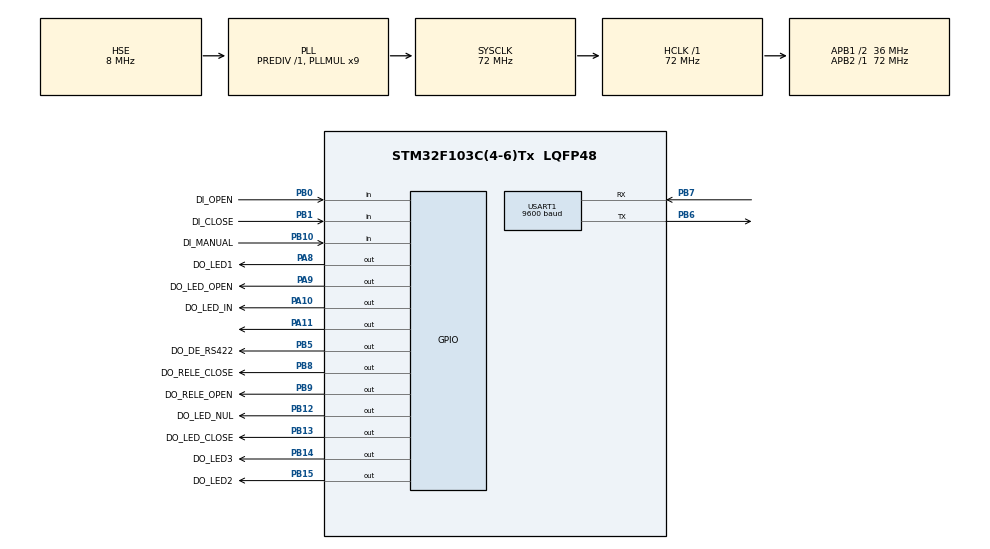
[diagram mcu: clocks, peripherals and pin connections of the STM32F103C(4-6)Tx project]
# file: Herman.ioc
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ADC1.Channel-0\#ChannelRegularConversion=ADC_CHANNEL_VREFINT
ADC1.NbrOfConversionFlag=1
ADC1.Rank-0\#ChannelRegularConversion=1
ADC1.SamplingTime-0\#ChannelRegularConversion=ADC_SAMPLETIME_1CYCLE_5
ADC1.master=1
FREERTOS.Tasks01=Task200mks,0,128,StartTask200mks,Default,NULL,Dynamic,NULL,NULL
FREERTOS.configTOTAL_HEAP_SIZE=1024
FREERTOS.configUSE_COUNTING_SEMAPHORES=1
IWDG.Prescaler=IWDG_PRESCALER_256
Mcu.Family=STM32F1
Mcu.Name=STM32F103C(4-6)Tx
Mcu.Package=LQFP48
NVIC.FLASH_IRQn=true\:5\:0\:false\:false\:true\:true\:true\:true
NVIC.PriorityGroup=NVIC_PRIORITYGROUP_4
NVIC.TIM1_UP_IRQn=true\:5\:0\:false\:false\:true\:true\:true\:true
NVIC.TIM3_IRQn=true\:15\:0\:false\:false\:true\:false\:false\:true
NVIC.TimeBase=TIM3_IRQn
NVIC.TimeBaseIP=TIM3
NVIC.USART1_IRQn=true\:5\:0\:false\:false\:true\:true\:true\:true
PA10.GPIO_Label=DO_LED_IN
PA10.GPIO_ModeDefaultOutputPP=GPIO_MODE_OUTPUT_OD
PA10.GPIO_PuPd=GPIO_NOPULL
PA10.GPIO_Speed=GPIO_SPEED_FREQ_LOW
PA10.PinState=GPIO_PIN_SET
PA10.Signal=GPIO_Output
PA11.Signal=GPIO_Output
PA13.Mode=Trace_Asynchronous_SW
PA13.Signal=SYS_JTMS-SWDIO
PA14.Mode=Trace_Asynchronous_SW
PA14.Signal=SYS_JTCK-SWCLK
PA8.GPIO_Label=DO_LED1
PA8.GPIO_ModeDefaultOutputPP=GPIO_MODE_OUTPUT_OD
PA8.GPIO_PuPd=GPIO_NOPULL
PA8.PinState=GPIO_PIN_SET
PA8.Signal=GPIO_Output
PA9.GPIO_Label=DO_LED_OPEN
PA9.GPIO_ModeDefaultOutputPP=GPIO_MODE_OUTPUT_OD
PA9.GPIO_PuPd=GPIO_NOPULL
PA9.GPIO_Speed=GPIO_SPEED_FREQ_LOW
PA9.PinState=GPIO_PIN_SET
PA9.Signal=GPIO_Output
PB0.GPIO_Label=DI_OPEN
PB0.GPIO_PuPd=GPIO_PULLDOWN
PB0.Signal=GPIO_Input
PB1.GPIO_Label=DI_CLOSE
PB1.GPIO_PuPd=GPIO_PULLDOWN
PB1.Signal=GPIO_Input
PB10.GPIO_Label=DI_MANUAL
PB10.GPIO_PuPd=GPIO_PULLDOWN
PB10.Signal=GPIO_Input
PB12.GPIO_Label=DO_LED_NUL
PB12.GPIO_ModeDefaultOutputPP=GPIO_MODE_OUTPUT_OD
PB12.GPIO_PuPd=GPIO_NOPULL
PB12.PinState=GPIO_PIN_SET
PB12.Signal=GPIO_Output
PB13.GPIO_Label=DO_LED_CLOSE
PB13.GPIO_ModeDefaultOutputPP=GPIO_MODE_OUTPUT_OD
PB13.GPIO_PuPd=GPIO_NOPULL
PB13.PinState=GPIO_PIN_SET
PB13.Signal=GPIO_Output
PB14.GPIO_Label=DO_LED3
PB14.GPIO_ModeDefaultOutputPP=GPIO_MODE_OUTPUT_OD
PB14.GPIO_PuPd=GPIO_NOPULL
PB14.PinState=GPIO_PIN_SET
PB14.Signal=GPIO_Output
PB15.GPIO_Label=DO_LED2
PB15.GPIO_ModeDefaultOutputPP=GPIO_MODE_OUTPUT_OD
PB15.GPIO_PuPd=GPIO_NOPULL
PB15.PinState=GPIO_PIN_SET
PB15.Signal=GPIO_Output
PB3.Mode=Trace_Asynchronous_SW
PB3.Signal=SYS_JTDO-TRACESWO
PB5.GPIO_Label=DO_DE_RS422
PB5.GPIO_Speed=GPIO_SPEED_FREQ_LOW
PB5.PinState=GPIO_PIN_RESET
PB5.Signal=GPIO_Output
PB6.Mode=Asynchronous
PB6.Signal=USART1_TX
PB7.Mode=Asynchronous
PB7.Signal=USART1_RX
PB8.GPIO_Label=DO_RELE_CLOSE
PB8.Signal=GPIO_Output
PB9.GPIO_Label=DO_RELE_OPEN
PB9.GPIO_ModeDefaultOutputPP=GPIO_MODE_OUTPUT_PP
PB9.Signal=GPIO_Output
PD0-OSC_IN.Mode=HSE-External-Oscillator
PD0-OSC_IN.Signal=RCC_OSC_IN
PD1-OSC_OUT.Mode=HSE-External-Oscillator
PD1-OSC_OUT.Signal=RCC_OSC_OUT
ProjectManager.HeapSize=0x1000
ProjectManager.StackSize=0x200
ProjectManager.TargetToolchain=MDK-ARM V5.27
RCC.ADCPresc=RCC_ADCPCLK2_DIV6
RCC.AHBFreq_Value=72000000
RCC.APB1CLKDivider=RCC_HCLK_DIV2
RCC.APB1Freq_Value=36000000
RCC.APB1TimFreq_Value=72000000
RCC.APB2Freq_Value=72000000
RCC.APB2TimFreq_Value=72000000
RCC.HCLKFreq_Value=72000000
RCC.PLLMUL=RCC_PLL_MUL9
RCC.PLLSourceVirtual=RCC_PLLSOURCE_HSE
RCC.PREFETCH_ENABLE=1
RCC.RCC_MCOSource=RCC_MCO1SOURCE_HSE
RCC.SYSCLKFreq_VALUE=72000000
RCC.SYSCLKSource=RCC_SYSCLKSOURCE_PLLCLK
RCC.USBFreq_Value=72000000
TIM1.AutoReloadPreload=TIM_AUTORELOAD_PRELOAD_DISABLE
TIM1.Period=9999
TIM1.Prescaler=71
USART1.BaudRate=9600
USART1.Parity=PARITY_EVEN
USART1.StopBits=STOPBITS_1
USART1.VirtualMode=VM_ASYNC
USART1.WordLength=WORDLENGTH_9B
VP_ADC1_Vref_Input.Mode=IN-Vrefint
VP_FREERTOS_VS_CMSIS_V1.Mode=CMSIS_V1
VP_IWDG_VS_IWDG.Mode=IWDG_Activate
VP_SYS_VS_tim3.Mode=TIM3
VP_TIM1_VS_ClockSourceINT.Mode=Internal
board=custom

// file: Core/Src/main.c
/* USER CODE BEGIN Header */
/**
  ******************************************************************************
  * @file           : main.c
  * @brief          : Main program body
  ******************************************************************************
  * @attention
  *
  * Copyright (c) 2022 STMicroelectronics.
  * All rights reserved.
  *
  * This software is licensed under terms that can be found in the LICENSE file
  * in the root directory of this software component.
  * If no LICENSE file comes with this software, it is provided AS-IS.
  *
  ******************************************************************************
  */
/* USER CODE END Header */
#include "main.h"
#include "cmsis_os.h"
#include "adc.h"
#include "iwdg.h"
#include "tim.h"
#include "usart.h"
#include "gpio.h"

/* USER CODE BEGIN PD */
extern void HAL_TIMx_PeriodElapsedCallback(TIM_HandleTypeDef *htim);
/* USER CODE END PD */

void SystemClock_Config(void);
void MX_FREERTOS_Init(void);

int main(void)
{

  /* MCU Configuration--------------------------------------------------------*/

  /* Reset of all peripherals, Initializes the Flash interface and the Systick. */
  HAL_Init();

  /* Configure the system clock */
  SystemClock_Config();

  /* Initialize all configured peripherals */
  MX_GPIO_Init();
  MX_ADC1_Init();
  MX_USART1_UART_Init();
  MX_TIM1_Init();
  MX_IWDG_Init();

  /* Call init function for freertos objects (in freertos.c) */
  MX_FREERTOS_Init();
  /* Start scheduler */
  osKernelStart();

  /* We should never get here as control is now taken by the scheduler */
  /* Infinite loop */
  while (1)
  {

  }
}

void SystemClock_Config(void)
{
  RCC_OscInitTypeDef RCC_OscInitStruct = {0};
  RCC_ClkInitTypeDef RCC_ClkInitStruct = {0};
  RCC_PeriphCLKInitTypeDef PeriphClkInit = {0};

  /** Initializes the RCC Oscillators according to the specified parameters
  * in the RCC_OscInitTypeDef structure.
  */
  RCC_OscInitStruct.OscillatorType = RCC_OSCILLATORTYPE_LSI|RCC_OSCILLATORTYPE_HSE;
  RCC_OscInitStruct.HSEState = RCC_HSE_ON;
  RCC_OscInitStruct.HSEPredivValue = RCC_HSE_PREDIV_DIV1;
  RCC_OscInitStruct.HSIState = RCC_HSI_ON;
  RCC_OscInitStruct.LSIState = RCC_LSI_ON;
  RCC_OscInitStruct.PLL.PLLState = RCC_PLL_ON;
  RCC_OscInitStruct.PLL.PLLSource = RCC_PLLSOURCE_HSE;
  RCC_OscInitStruct.PLL.PLLMUL = RCC_PLL_MUL9;
  if (HAL_RCC_OscConfig(&RCC_OscInitStruct) != HAL_OK)
  {
    Error_Handler();
  }
  /** Initializes the CPU, AHB and APB buses clocks
  */
  RCC_ClkInitStruct.ClockType = RCC_CLOCKTYPE_HCLK|RCC_CLOCKTYPE_SYSCLK
                              |RCC_CLOCKTYPE_PCLK1|RCC_CLOCKTYPE_PCLK2;
  RCC_ClkInitStruct.SYSCLKSource = RCC_SYSCLKSOURCE_PLLCLK;
  RCC_ClkInitStruct.AHBCLKDivider = RCC_SYSCLK_DIV1;
  RCC_ClkInitStruct.APB1CLKDivider = RCC_HCLK_DIV2;
  RCC_ClkInitStruct.APB2CLKDivider = RCC_HCLK_DIV1;

  if (HAL_RCC_ClockConfig(&RCC_ClkInitStruct, FLASH_LATENCY_2) != HAL_OK)
  {
    Error_Handler();
  }
  PeriphClkInit.PeriphClockSelection = RCC_PERIPHCLK_ADC;
  PeriphClkInit.AdcClockSelection = RCC_ADCPCLK2_DIV6;
  if (HAL_RCCEx_PeriphCLKConfig(&PeriphClkInit) != HAL_OK)
  {
    Error_Handler();
  }
}

void HAL_TIM_PeriodElapsedCallback(TIM_HandleTypeDef *htim)
{
  if (htim->Instance == TIM3) {
    HAL_IncTick();
  }
  /* USER CODE BEGIN Callback 1 */
  else {
    HAL_TIMx_PeriodElapsedCallback(&htim1);
  }
  /* USER CODE END Callback 1 */
}

void Error_Handler(void)
{
  __disable_irq();
  while (1)
  {
  }
}

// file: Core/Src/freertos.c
/* USER CODE BEGIN Header */
/**
  ******************************************************************************
  * File Name          : freertos.c
  * Description        : Code for freertos applications
  ******************************************************************************
  * @attention
  *
  * Copyright (c) 2022 STMicroelectronics.
  * All rights reserved.
  *
  * This software is licensed under terms that can be found in the LICENSE file
  * in the root directory of this software component.
  * If no LICENSE file comes with this software, it is provided AS-IS.
  *
  ******************************************************************************
  */
/* USER CODE END Header */

#include "FreeRTOS.h"
#include "task.h"
#include "main.h"
#include "cmsis_os.h"

/* USER CODE BEGIN PM */
extern void period200mksTsk(void);
/* USER CODE END PM */

osThreadId Task200mksHandle;

/* USER CODE BEGIN FunctionPrototypes */
void StartTask200mks(void const * argument);
/* USER CODE END FunctionPrototypes */

void StartTask200mks(void const * argument);

void MX_FREERTOS_Init(void); /* (MISRA C 2004 rule 8.1) */

/* GetIdleTaskMemory prototype (linked to static allocation support) */
void vApplicationGetIdleTaskMemory( StaticTask_t **ppxIdleTaskTCBBuffer, StackType_t **ppxIdleTaskStackBuffer, uint32_t *pulIdleTaskStackSize );

/* USER CODE BEGIN GET_IDLE_TASK_MEMORY */
static StaticTask_t xIdleTaskTCBBuffer;
static StackType_t xIdleStack[configMINIMAL_STACK_SIZE];

void vApplicationGetIdleTaskMemory( StaticTask_t **ppxIdleTaskTCBBuffer, StackType_t **ppxIdleTaskStackBuffer, uint32_t *pulIdleTaskStackSize )
{
  *ppxIdleTaskTCBBuffer = &xIdleTaskTCBBuffer;
  *ppxIdleTaskStackBuffer = &xIdleStack[0];
  *pulIdleTaskStackSize = configMINIMAL_STACK_SIZE;
  /* place for user code */
}
/* USER CODE END GET_IDLE_TASK_MEMORY */

void MX_FREERTOS_Init(void) {

  /* Create the thread(s) */
  /* definition and creation of Task200mks */
  osThreadDef(Task200mks, StartTask200mks, osPriorityNormal, 0, 128);
  Task200mksHandle = osThreadCreate(osThread(Task200mks), NULL);

}

void StartTask200mks(void const * argument)
{
  /* USER CODE BEGIN StartTask200mks */
  /* Infinite loop */
  period200mksTsk();
  /* USER CODE END StartTask200mks */
}
